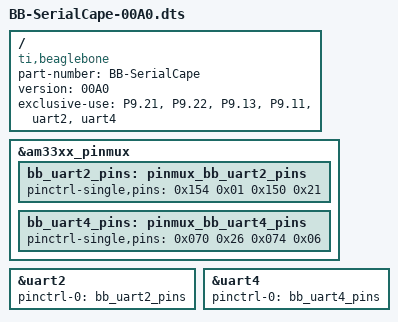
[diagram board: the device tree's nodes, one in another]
/dts-v1/;
/plugin/;

//#include <dt-bindings/board/am335x-bbw-bbb-base.h>
//#include <dt-bindings/pinctrl/am33xx.h>

/ {
    compatible = "ti,beaglebone", "ti,beaglebone-black";

    part-number = "BB-SerialCape";
    version = "00A0";

    /* state the resources this cape uses */
    exclusive-use =
        /* the pin header uses */
        "P9.21", /* uart2_txd */
        "P9.22", /* uart2_rxd */

        "P9.13", /* uart4_txd */
        "P9.11", /* uart4_rxd */

        /* the hardware ip uses */
        "uart2",
        "uart4";

    fragment@0 {
        target = <&am33xx_pinmux>;
        __overlay__ {
            bb_uart2_pins: pinmux_bb_uart2_pins {
                pinctrl-single,pins = <
                    0x154 0x01 /* spi0_d0.uart2_txd */
                    0x150 0x21 /* spi0_sclk.uart2_rxd */
                >;
            };

            bb_uart4_pins: pinmux_bb_uart4_pins {
                pinctrl-single,pins = <
                    0x070 0x26 /* gpmc_wait0.uart4_rxd_mux2 */
                    0x074 0x06 /* gpmc_wpn.uart4_txd_mux2 */
                >;
            };
        };
    };

    fragment@1 {
        target = <&uart2>;
        __overlay__ {
            status = "okay";
            pinctrl-names = "default";
            pinctrl-0 = <&bb_uart2_pins>;
        };
    };

    fragment@2 {
        target = <&uart4>;
        __overlay__ {
            status = "okay";
            pinctrl-names = "default";
            pinctrl-0 = <&bb_uart4_pins>;
        };
    };

};
